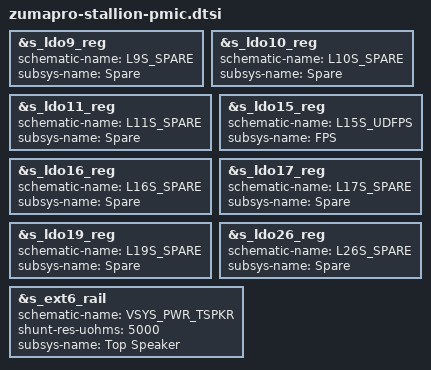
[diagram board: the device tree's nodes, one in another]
// SPDX-License-Identifier: GPL-2.0-only
/*
 * Stallion pmic device tree source
 *
 * Copyright 2025 Google LLC
 *
 */

&s_ldo9_reg {
	schematic-name = "L9S_SPARE";
	subsys-name = "Spare";
};

&s_ldo10_reg {
	schematic-name = "L10S_SPARE";
	subsys-name = "Spare";
};

&s_ldo11_reg {
	schematic-name = "L11S_SPARE";
	subsys-name = "Spare";
};

&s_ldo15_reg {
	schematic-name = "L15S_UDFPS";
	subsys-name = "FPS";
};

&s_ldo16_reg {
	schematic-name = "L16S_SPARE";
	subsys-name = "Spare";
};

&s_ldo17_reg {
	schematic-name = "L17S_SPARE";
	subsys-name = "Spare";
};

&s_ldo19_reg {
	schematic-name = "L19S_SPARE";
	subsys-name = "Spare";
};

&s_ldo26_reg {
	schematic-name = "L26S_SPARE";
	subsys-name = "Spare";
};

&s_ext6_rail {
	schematic-name = "VSYS_PWR_TSPKR";
	shunt-res-uohms = <5000>;
	subsys-name = "Top Speaker";
};
